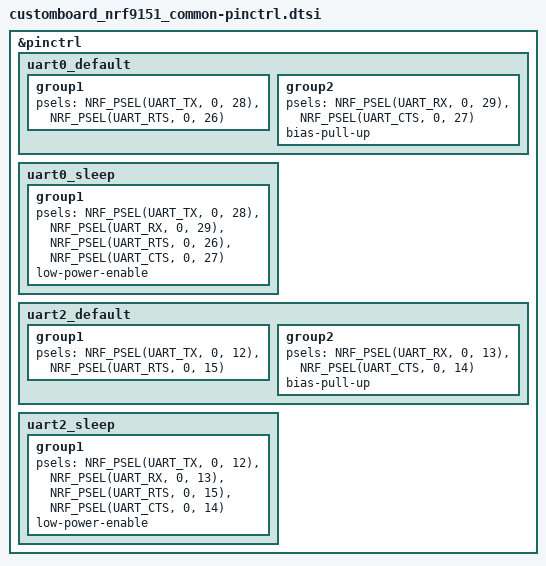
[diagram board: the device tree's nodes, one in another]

&pinctrl {
  uart0_default: uart0_default {
    group1 {
      psels = <NRF_PSEL(UART_TX, 0, 28)>,
        <NRF_PSEL(UART_RTS, 0, 26)>;
    };
    group2 {
      psels = <NRF_PSEL(UART_RX, 0, 29)>,
        <NRF_PSEL(UART_CTS, 0, 27)>;
      bias-pull-up;
    };
  };

  uart0_sleep: uart0_sleep {
    group1 {
      psels = <NRF_PSEL(UART_TX, 0, 28)>,
        <NRF_PSEL(UART_RX, 0, 29)>,
        <NRF_PSEL(UART_RTS, 0, 26)>,
        <NRF_PSEL(UART_CTS, 0, 27)>;
      low-power-enable;
    };
  };

  uart2_default: uart2_default {
    group1 {
      psels = <NRF_PSEL(UART_TX, 0, 12)>,
        <NRF_PSEL(UART_RTS, 0, 15)>;
    };
    group2 {
      psels = <NRF_PSEL(UART_RX, 0, 13)>,
        <NRF_PSEL(UART_CTS, 0, 14)>;
      bias-pull-up;
    };
  };

  uart2_sleep: uart2_sleep {
    group1 {
      psels = <NRF_PSEL(UART_TX, 0, 12)>,
        <NRF_PSEL(UART_RX, 0, 13)>,
        <NRF_PSEL(UART_RTS, 0, 15)>,
        <NRF_PSEL(UART_CTS, 0, 14)>;
      low-power-enable;
    };
  };
};

